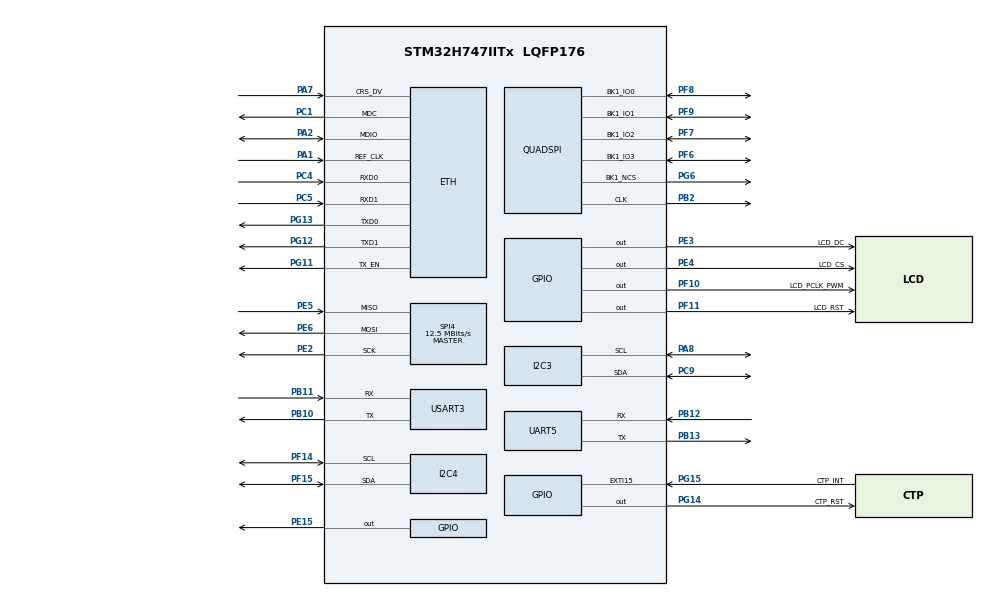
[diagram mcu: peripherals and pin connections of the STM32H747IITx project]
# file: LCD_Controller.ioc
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CORTEX_M7.CPU_DCache=Enabled
CORTEX_M7.CPU_ICache=Enabled
CORTEX_M7.default_mode_Activation=1
CortexM4.IPs=BDMA,CORTEX_M4\:I,DMA,FATFS_M4\:I,FREERTOS_M4\:I,GPIO,IWDG2\:I,MDMA,NVIC2\:I,OPENAMP_M4\:I,PDM2PCM_M4\:I,PWR,RCC,RESMGR_UTILITY,SYS_M4\:I,USB_DEVICE_M4\:I,USB_HOST_M4\:I,VREFBUF,WWDG2\:I
CortexM7.IPs=BDMA\:I,CORTEX_M7\:I,DMA\:I,FATFS_M7\:I,FREERTOS_M7\:I,GPIO\:I,IWDG1\:I,MDMA\:I,NVIC1\:I,OPENAMP_M7\:I,PDM2PCM_M7\:I,PWR\:I,RCC\:I,RESMGR_UTILITY\:I,SYS\:I,USB_DEVICE_M7\:I,USB_HOST_M7\:I,VREFBUF\:I,WWDG1\:I,MEMORYMAP\:I,TIM6\:I,ETH\:I,LWIP\:I,DEBUG\:I,UART5\:I,USART3\:I,SPI4\:I,I2C4\:I,QUADSPI\:I,I2C3\:I
CortexM7.Pins=PE3,PE4,PF10,PF11,PE15,PG14,PG15
ETH.MediaInterface=HAL_ETH_RMII_MODE
ETH.RxDescAddress=0x30040000
ETH.TxDescAddress=0x30040100
FREERTOS_M7.HEAP_NUMBER=3
FREERTOS_M7.Tasks01=defaultTask,24,2048,StartDefaultTask,Default,NULL,Dynamic,NULL,NULL
FREERTOS_M7.configCHECK_FOR_STACK_OVERFLOW=1
FREERTOS_M7.configMAX_TASK_NAME_LEN=50
FREERTOS_M7.configMINIMAL_STACK_SIZE=512
FREERTOS_M7.configTOTAL_HEAP_SIZE=204800
FREERTOS_M7.configUSE_NEWLIB_REENTRANT=1
I2C3.Timing=0x10C0ECFF
I2C4.Speed=50
I2C4.Timing=0x50404CFD
LWIP.BSP.number=1
LWIP.DEFAULT_THREAD_STACKSIZE=2048
LWIP.GATEWAY_ADDRESS=010.002.001.001
LWIP.IP_ADDRESS=010.002.001.110
LWIP.LWIP_DHCP=0
LWIP.LWIP_HTTPD=1
LWIP.LWIP_RAM_HEAP_POINTER=0x30020000
LWIP.MEM_SIZE=131048
LWIP.NETMASK_ADDRESS=255.255.255.000
LWIP.TCPIP_THREAD_STACKSIZE=2048
LWIP.TCP_MSS=1460
LWIP.TCP_SND_BUF=5840
LWIP.TCP_SND_QUEUELEN=16
LWIP.TCP_WND=5840
LWIP.Version=v2.1.2_Cube
LWIP0.BSP.STBoard=false
LWIP0.BSP.api=BSP_COMPONENT_DRIVER
LWIP0.BSP.component=LAN8742
LWIP0.BSP.instance=LAN8742
LWIP0.BSP.name=Driver_PHY
LWIP0.BSP.semaphore=S_LAN8742
LWIP0.BSP.solution=LAN8742
Mcu.Family=STM32H7
Mcu.Name=STM32H747IITx
Mcu.Package=LQFP176
NVIC1.ETH_IRQn=true\:5\:0\:false\:false\:true\:true\:true\:true\:true
NVIC1.EXTI15_10_IRQn=true\:5\:0\:false\:false\:true\:false\:true\:true\:true
NVIC1.PriorityGroup=NVIC_PRIORITYGROUP_4
NVIC1.TIM6_DAC_IRQn=true\:15\:0\:false\:false\:true\:false\:false\:true\:true
NVIC1.TimeBase=TIM6_DAC_IRQn
NVIC1.TimeBaseIP=TIM6
NVIC2.PriorityGroup=NVIC_PRIORITYGROUP_4
PA1.Mode=RMII
PA1.PinAttribute=CortexM7
PA1.Signal=ETH_REF_CLK
PA13\ (JTMS/SWDIO).Mode=Serial_Wire
PA13\ (JTMS/SWDIO).PinAttribute=CortexM7
PA13\ (JTMS/SWDIO).Signal=DEBUG_JTMS-SWDIO
PA14\ (JTCK/SWCLK).Mode=Serial_Wire
PA14\ (JTCK/SWCLK).PinAttribute=CortexM7
PA14\ (JTCK/SWCLK).Signal=DEBUG_JTCK-SWCLK
PA2.Mode=RMII
PA2.PinAttribute=CortexM7
PA2.Signal=ETH_MDIO
PA7.Mode=RMII
PA7.PinAttribute=CortexM7
PA7.Signal=ETH_CRS_DV
PA8.Mode=I2C
PA8.PinAttribute=CortexM7
PA8.Signal=I2C3_SCL
PB10.Mode=Asynchronous
PB10.PinAttribute=CortexM7
PB10.Signal=USART3_TX
PB11.Mode=Asynchronous
PB11.PinAttribute=CortexM7
PB11.Signal=USART3_RX
PB12.Mode=Asynchronous
PB12.PinAttribute=CortexM7
PB12.Signal=UART5_RX
PB13.Mode=Asynchronous
PB13.PinAttribute=CortexM7
PB13.Signal=UART5_TX
PB2.Mode=Single Bank 1
PB2.PinAttribute=CortexM7
PB2.Signal=QUADSPI_CLK
PC1.Mode=RMII
PC1.PinAttribute=CortexM7
PC1.Signal=ETH_MDC
PC4.Mode=RMII
PC4.PinAttribute=CortexM7
PC4.Signal=ETH_RXD0
PC5.Mode=RMII
PC5.PinAttribute=CortexM7
PC5.Signal=ETH_RXD1
PC9.Mode=I2C
PC9.PinAttribute=CortexM7
PC9.Signal=I2C3_SDA
PE15.PinAttribute=CortexM7
PE15.PinState=GPIO_PIN_SET
PE15.Signal=GPIO_Output
PE2.Mode=Full_Duplex_Master
PE2.PinAttribute=CortexM7
PE2.Signal=SPI4_SCK
PE3.GPIO_Label=LCD_DC
PE3.GPIO_Speed=GPIO_SPEED_FREQ_VERY_HIGH
PE3.PinAttribute=CortexM7
PE3.PinState=GPIO_PIN_SET
PE3.Signal=GPIO_Output
PE4.GPIO_Label=LCD_CS
PE4.GPIO_Speed=GPIO_SPEED_FREQ_VERY_HIGH
PE4.PinAttribute=CortexM7
PE4.PinState=GPIO_PIN_SET
PE4.Signal=GPIO_Output
PE5.Mode=Full_Duplex_Master
PE5.PinAttribute=CortexM7
PE5.Signal=SPI4_MISO
PE6.Mode=Full_Duplex_Master
PE6.PinAttribute=CortexM7
PE6.Signal=SPI4_MOSI
PF10.GPIO_Label=LCD_PCLK_PWM
PF10.GPIO_Speed=GPIO_SPEED_FREQ_VERY_HIGH
PF10.PinAttribute=CortexM7
PF10.PinState=GPIO_PIN_SET
PF10.Signal=GPIO_Output
PF11.GPIO_Label=LCD_RST
PF11.GPIO_Speed=GPIO_SPEED_FREQ_VERY_HIGH
PF11.PinAttribute=CortexM7
PF11.PinState=GPIO_PIN_SET
PF11.Signal=GPIO_Output
PF14.GPIO_Pu=GPIO_PULLUP
PF14.GPIO_Speed=GPIO_SPEED_FREQ_VERY_HIGH
PF14.Mode=I2C
PF14.PinAttribute=CortexM7
PF14.Signal=I2C4_SCL
PF15.GPIO_Pu=GPIO_PULLUP
PF15.GPIO_Speed=GPIO_SPEED_FREQ_VERY_HIGH
PF15.Mode=I2C
PF15.PinAttribute=CortexM7
PF15.Signal=I2C4_SDA
PF6.Mode=Single Bank 1
PF6.PinAttribute=CortexM7
PF6.Signal=QUADSPI_BK1_IO3
PF7.Mode=Single Bank 1
PF7.PinAttribute=CortexM7
PF7.Signal=QUADSPI_BK1_IO2
PF8.Mode=Single Bank 1
PF8.PinAttribute=CortexM7
PF8.Signal=QUADSPI_BK1_IO0
PF9.Mode=Single Bank 1
PF9.PinAttribute=CortexM7
PF9.Signal=QUADSPI_BK1_IO1
PG11.Mode=RMII
PG11.PinAttribute=CortexM7
PG11.Signal=ETH_TX_EN
PG12.Mode=RMII
PG12.PinAttribute=CortexM7
PG12.Signal=ETH_TXD1
PG13.Mode=RMII
PG13.PinAttribute=CortexM7
PG13.Signal=ETH_TXD0
PG14.GPIO_Label=CTP_RST
PG14.GPIO_Speed=GPIO_SPEED_FREQ_HIGH
PG14.PinAttribute=CortexM7
PG14.PinState=GPIO_PIN_SET
PG14.Signal=GPIO_Output
PG15.GPIO_Label=CTP_INT
PG15.GPIO_ModeDefaultEXTI=GPIO_MODE_IT_FALLING
PG15.PinAttribute=CortexM7
PG15.Signal=GPXTI15
PG6.Mode=Single Bank 1
PG6.PinAttribute=CortexM7
PG6.Signal=QUADSPI_BK1_NCS
PH0-OSC_IN\ (PH0).Mode=HSE-External-Oscillator
PH0-OSC_IN\ (PH0).PinAttribute=Free
PH0-OSC_IN\ (PH0).Signal=RCC_OSC_IN
PH1-OSC_OUT\ (PH1).Mode=HSE-External-Oscillator
PH1-OSC_OUT\ (PH1).PinAttribute=Free
PH1-OSC_OUT\ (PH1).Signal=RCC_OSC_OUT
ProjectManager.HeapSize=M4-0x200,M7-0x200
ProjectManager.StackSize=M4-0x400,M7-0x400
ProjectManager.TargetToolchain=STM32CubeIDE
QUADSPI.ChipSelectHighTime=QSPI_CS_HIGH_TIME_2_CYCLE
QUADSPI.ClockPrescaler=8
QUADSPI.FifoThreshold=4
QUADSPI.FlashSize=21
QUADSPI.SampleShifting=QSPI_SAMPLE_SHIFTING_HALFCYCLE
RCC.ADCFreq_Value=50390625
RCC.APB1Freq_Value=100000000
RCC.APB2Freq_Value=100000000
RCC.APB3Freq_Value=100000000
RCC.APB4Freq_Value=100000000
RCC.CortexFreq_Value=400000000
RCC.D1PPRE=RCC_APB3_DIV2
RCC.D2PPRE1=RCC_APB1_DIV2
RCC.D2PPRE2=RCC_APB2_DIV2
RCC.D3PPRE=RCC_APB4_DIV2
RCC.DIVM1=2
RCC.DIVN1=64
RCC.HCLKFreq_Value=200000000
RCC.HPRE=RCC_HCLK_DIV2
RCC.PLLFRACN=0
RCC.PLLSourceVirtual=RCC_PLLSOURCE_HSE
RCC.SYSCLKFreq_VALUE=400000000
RCC.SYSCLKSource=RCC_SYSCLKSOURCE_PLLCLK
RCC.USBFreq_Value=400000000
SPI4.BaudRatePrescaler=SPI_BAUDRATEPRESCALER_8
SPI4.CalculateBaudRate=12.5 MBits/s
SPI4.DataSize=SPI_DATASIZE_8BIT
SPI4.Direction=SPI_DIRECTION_2LINES
SPI4.Mode=SPI_MODE_MASTER
SPI4.VirtualType=VM_MASTER
SYS.userName=SYS_M7
USART3.VirtualMode-Asynchronous=VM_ASYNC
VP_FREERTOS_M7_VS_CMSIS_V2.Mode=CMSIS_V2
VP_LWIP_VS_Enabled.Mode=Enabled
VP_MEMORYMAP_VS_MEMORYMAP.Mode=CurAppReg
VP_SYS_M4_VS_Systick.Mode=SysTick
VP_SYS_VS_tim6.Mode=TIM6
board=custom

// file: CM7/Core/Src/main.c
/* USER CODE BEGIN Header */
/**
  ******************************************************************************
  * @file           : main.c
  * @brief          : Main program body
  ******************************************************************************
  * @attention
  *
  * Copyright (c) 2025 STMicroelectronics.
  * All rights reserved.
  *
  * This software is licensed under terms that can be found in the LICENSE file
  * in the root directory of this software component.
  * If no LICENSE file comes with this software, it is provided AS-IS.
  *
  ******************************************************************************
  */
/* USER CODE END Header */

#include "main.h"
#include "cmsis_os.h"
#include "lwip.h"

/* USER CODE BEGIN Includes */
#include "freertos_custom.h"
/* USER CODE END Includes */

/* USER CODE BEGIN PD */
#define DUAL_CORE_BOOT_SYNC_SEQUENCE
#if defined(DUAL_CORE_BOOT_SYNC_SEQUENCE)
#ifndef HSEM_ID_0
#define HSEM_ID_0 (0U)
#endif
#endif
/* USER CODE END PD */

I2C_HandleTypeDef hi2c3;
I2C_HandleTypeDef hi2c4;
QSPI_HandleTypeDef hqspi;
SPI_HandleTypeDef hspi4;
UART_HandleTypeDef huart5;
UART_HandleTypeDef huart3;

/* Definitions for defaultTask */
osThreadId_t defaultTaskHandle;
const osThreadAttr_t defaultTask_attributes = {
  .name = "defaultTask",
  .stack_size = 10000 * 4,
  .priority = (osPriority_t) osPriorityNormal,
};

void SystemClock_Config(void);
static void MPU_Config(void);
static void MX_GPIO_Init(void);
static void MX_SPI4_Init(void);
static void MX_UART5_Init(void);
static void MX_USART3_UART_Init(void);
static void MX_I2C4_Init(void);
static void MX_QUADSPI_Init(void);
static void MX_I2C3_Init(void);
void StartDefaultTask(void *argument);
/* USER CODE BEGIN PFP */
static void simple_httpd_init(void *arg);
/* USER CODE END PFP */

/* USER CODE BEGIN 0 */
int __io_putchar(int ch)
{
    HAL_UART_Transmit(&huart5, (uint8_t *)&ch, 1, 100);
    return ch;
}
/* USER CODE END 0 */

int main(void)
{

  /* MPU Configuration--------------------------------------------------------*/
  MPU_Config();

  /* Enable CPU Cache */
  SCB_EnableICache();
  SCB_EnableDCache();

  /* MCU Configuration--------------------------------------------------------*/
  HAL_Init();
  SystemClock_Config();

  /* Initialize all configured peripherals */
  MX_GPIO_Init();
  MX_SPI4_Init();
  MX_UART5_Init();
  MX_USART3_UART_Init();
  MX_I2C4_Init();
  MX_QUADSPI_Init();
  MX_I2C3_Init();

  /* Initialize Ethernet backend (LwIP CGI/SSI setup) */
  Ethernet_BackendInfrastructure_Init();

  /* Init FreeRTOS kernel */
  osKernelInitialize();

  /* Create application threads */
  MainProcessFreertosInit();

  /* Default LWIP task */
  defaultTaskHandle = osThreadNew(StartDefaultTask, NULL, &defaultTask_attributes);

  /* Start scheduler */
  osKernelStart();

  /* Infinite loop */
  while (1)
  {
  }
}

void SystemClock_Config(void)
{
  RCC_OscInitTypeDef RCC_OscInitStruct = {0};
  RCC_ClkInitTypeDef RCC_ClkInitStruct = {0};

  HAL_PWREx_ConfigSupply(PWR_DIRECT_SMPS_SUPPLY);
  __HAL_PWR_VOLTAGESCALING_CONFIG(PWR_REGULATOR_VOLTAGE_SCALE1);
  while(!__HAL_PWR_GET_FLAG(PWR_FLAG_VOSRDY)) {}

  RCC_OscInitStruct.OscillatorType = RCC_OSCILLATORTYPE_HSE;
  RCC_OscInitStruct.HSEState = RCC_HSE_ON;
  RCC_OscInitStruct.PLL.PLLState = RCC_PLL_ON;
  RCC_OscInitStruct.PLL.PLLSource = RCC_PLLSOURCE_HSE;
  RCC_OscInitStruct.PLL.PLLM = 2;
  RCC_OscInitStruct.PLL.PLLN = 64;
  RCC_OscInitStruct.PLL.PLLP = 2;
  RCC_OscInitStruct.PLL.PLLQ = 2;
  RCC_OscInitStruct.PLL.PLLR = 2;
  RCC_OscInitStruct.PLL.PLLRGE = RCC_PLL1VCIRANGE_3;
  RCC_OscInitStruct.PLL.PLLVCOSEL = RCC_PLL1VCOWIDE;
  RCC_OscInitStruct.PLL.PLLFRACN = 0;
  if (HAL_RCC_OscConfig(&RCC_OscInitStruct) != HAL_OK) { Error_Handler(); }

  RCC_ClkInitStruct.ClockType = RCC_CLOCKTYPE_HCLK | RCC_CLOCKTYPE_SYSCLK
                              | RCC_CLOCKTYPE_PCLK1 | RCC_CLOCKTYPE_PCLK2
                              | RCC_CLOCKTYPE_D3PCLK1 | RCC_CLOCKTYPE_D1PCLK1;
  RCC_ClkInitStruct.SYSCLKSource = RCC_SYSCLKSOURCE_PLLCLK;
  RCC_ClkInitStruct.SYSCLKDivider = RCC_SYSCLK_DIV1;
  RCC_ClkInitStruct.AHBCLKDivider = RCC_HCLK_DIV2;
  RCC_ClkInitStruct.APB3CLKDivider = RCC_APB3_DIV2;
  RCC_ClkInitStruct.APB1CLKDivider = RCC_APB1_DIV2;
  RCC_ClkInitStruct.APB2CLKDivider = RCC_APB2_DIV2;
  RCC_ClkInitStruct.APB4CLKDivider = RCC_APB4_DIV2;

  if (HAL_RCC_ClockConfig(&RCC_ClkInitStruct, FLASH_LATENCY_2) != HAL_OK)
  {
    Error_Handler();
  }
}

/* --------------------------- Peripherals Init ---------------------------- */

static void MX_I2C3_Init(void)
{
  hi2c3.Instance = I2C3;
  hi2c3.Init.Timing = 0x10C0ECFF;
  hi2c3.Init.OwnAddress1 = 0;
  hi2c3.Init.AddressingMode = I2C_ADDRESSINGMODE_7BIT;
  hi2c3.Init.DualAddressMode = I2C_DUALADDRESS_DISABLE;
  hi2c3.Init.OwnAddress2 = 0;
  hi2c3.Init.OwnAddress2Masks = I2C_OA2_NOMASK;
  hi2c3.Init.GeneralCallMode = I2C_GENERALCALL_DISABLE;
  hi2c3.Init.NoStretchMode = I2C_NOSTRETCH_DISABLE;
  if (HAL_I2C_Init(&hi2c3) != HAL_OK) { Error_Handler(); }
  if (HAL_I2CEx_ConfigAnalogFilter(&hi2c3, I2C_ANALOGFILTER_ENABLE) != HAL_OK) { Error_Handler(); }
  if (HAL_I2CEx_ConfigDigitalFilter(&hi2c3, 0) != HAL_OK) { Error_Handler(); }
}

static void MX_I2C4_Init(void)
{
  hi2c4.Instance = I2C4;
  hi2c4.Init.Timing = 0x50404CFD;
  hi2c4.Init.OwnAddress1 = 0;
  hi2c4.Init.AddressingMode = I2C_ADDRESSINGMODE_7BIT;
  hi2c4.Init.DualAddressMode = I2C_DUALADDRESS_DISABLE;
  hi2c4.Init.OwnAddress2 = 0;
  hi2c4.Init.OwnAddress2Masks = I2C_OA2_NOMASK;
  hi2c4.Init.GeneralCallMode = I2C_GENERALCALL_DISABLE;
  hi2c4.Init.NoStretchMode = I2C_NOSTRETCH_DISABLE;
  if (HAL_I2C_Init(&hi2c4) != HAL_OK) { Error_Handler(); }
  if (HAL_I2CEx_ConfigAnalogFilter(&hi2c4, I2C_ANALOGFILTER_ENABLE) != HAL_OK) { Error_Handler(); }
  if (HAL_I2CEx_ConfigDigitalFilter(&hi2c4, 0) != HAL_OK) { Error_Handler(); }
}

static void MX_QUADSPI_Init(void)
{
  hqspi.Instance = QUADSPI;
  hqspi.Init.ClockPrescaler = 8;
  hqspi.Init.FifoThreshold = 4;
  hqspi.Init.SampleShifting = QSPI_SAMPLE_SHIFTING_HALFCYCLE;
  hqspi.Init.FlashSize = 21;
  hqspi.Init.ChipSelectHighTime = QSPI_CS_HIGH_TIME_2_CYCLE;
  hqspi.Init.ClockMode = QSPI_CLOCK_MODE_0;
  hqspi.Init.FlashID = QSPI_FLASH_ID_1;
  hqspi.Init.DualFlash = QSPI_DUALFLASH_DISABLE;
  if (HAL_QSPI_Init(&hqspi) != HAL_OK) { Error_Handler(); }
}

static void MX_SPI4_Init(void)
{
  hspi4.Instance = SPI4;
  hspi4.Init.Mode = SPI_MODE_MASTER;
  hspi4.Init.Direction = SPI_DIRECTION_2LINES;
  hspi4.Init.DataSize = SPI_DATASIZE_8BIT;
  hspi4.Init.CLKPolarity = SPI_POLARITY_LOW;
  hspi4.Init.CLKPhase = SPI_PHASE_1EDGE;
  hspi4.Init.NSS = SPI_NSS_SOFT;
  hspi4.Init.BaudRatePrescaler = SPI_BAUDRATEPRESCALER_8;
  hspi4.Init.FirstBit = SPI_FIRSTBIT_MSB;
  hspi4.Init.TIMode = SPI_TIMODE_DISABLE;
  hspi4.Init.CRCCalculation = SPI_CRCCALCULATION_DISABLE;
  hspi4.Init.CRCPolynomial = 0x0;
  hspi4.Init.NSSPMode = SPI_NSS_PULSE_ENABLE;
  hspi4.Init.NSSPolarity = SPI_NSS_POLARITY_LOW;
  hspi4.Init.FifoThreshold = SPI_FIFO_THRESHOLD_01DATA;
  if (HAL_SPI_Init(&hspi4) != HAL_OK) { Error_Handler(); }
}

static void MX_UART5_Init(void)
{
  huart5.Instance = UART5;
  huart5.Init.BaudRate = 115200;
  huart5.Init.WordLength = UART_WORDLENGTH_8B;
  huart5.Init.StopBits = UART_STOPBITS_1;
  huart5.Init.Parity = UART_PARITY_NONE;
  huart5.Init.Mode = UART_MODE_TX_RX;
  huart5.Init.HwFlowCtl = UART_HWCONTROL_NONE;
  huart5.Init.OverSampling = UART_OVERSAMPLING_16;
  huart5.Init.OneBitSampling = UART_ONE_BIT_SAMPLE_DISABLE;
  huart5.Init.ClockPrescaler = UART_PRESCALER_DIV1;
  huart5.AdvancedInit.AdvFeatureInit = UART_ADVFEATURE_NO_INIT;
  if (HAL_UART_Init(&huart5) != HAL_OK) { Error_Handler(); }
}

static void MX_USART3_UART_Init(void)
{
  huart3.Instance = USART3;
  huart3.Init.BaudRate = 115200;
  huart3.Init.WordLength = UART_WORDLENGTH_8B;
  huart3.Init.StopBits = UART_STOPBITS_1;
  huart3.Init.Parity = UART_PARITY_NONE;
  huart3.Init.Mode = UART_MODE_TX_RX;
  huart3.Init.HwFlowCtl = UART_HWCONTROL_NONE;
  huart3.Init.OverSampling = UART_OVERSAMPLING_16;
  huart3.Init.OneBitSampling = UART_ONE_BIT_SAMPLE_DISABLE;
  huart3.Init.ClockPrescaler = UART_PRESCALER_DIV1;
  huart3.AdvancedInit.AdvFeatureInit = UART_ADVFEATURE_NO_INIT;
  if (HAL_UART_Init(&huart3) != HAL_OK) { Error_Handler(); }
}

/* --------------------------- GPIO Init ---------------------------- */

static void MX_GPIO_Init(void)
{
  GPIO_InitTypeDef GPIO_InitStruct = {0};

  __HAL_RCC_GPIOE_CLK_ENABLE();
  __HAL_RCC_GPIOF_CLK_ENABLE();
  __HAL_RCC_GPIOC_CLK_ENABLE();
  __HAL_RCC_GPIOA_CLK_ENABLE();
  __HAL_RCC_GPIOB_CLK_ENABLE();
  __HAL_RCC_GPIOG_CLK_ENABLE();

  HAL_GPIO_WritePin(GPIOE, LCD_DC_Pin | LCD_CS_Pin | GPIO_PIN_15, GPIO_PIN_SET);
  HAL_GPIO_WritePin(GPIOF, LCD_PCLK_PWM_Pin | LCD_RST_Pin, GPIO_PIN_SET);
  HAL_GPIO_WritePin(CTP_RST_GPIO_Port, CTP_RST_Pin, GPIO_PIN_SET);

  GPIO_InitStruct.Pin = LCD_DC_Pin | LCD_CS_Pin;
  GPIO_InitStruct.Mode = GPIO_MODE_OUTPUT_PP;
  GPIO_InitStruct.Pull = GPIO_NOPULL;
  GPIO_InitStruct.Speed = GPIO_SPEED_FREQ_VERY_HIGH;
  HAL_GPIO_Init(GPIOE, &GPIO_InitStruct);

  GPIO_InitStruct.Pin = LCD_PCLK_PWM_Pin | LCD_RST_Pin;
  GPIO_InitStruct.Mode = GPIO_MODE_OUTPUT_PP;
  GPIO_InitStruct.Pull = GPIO_NOPULL;
  GPIO_InitStruct.Speed = GPIO_SPEED_FREQ_VERY_HIGH;
  HAL_GPIO_Init(GPIOF, &GPIO_InitStruct);

  GPIO_InitStruct.Pin = CTP_RST_Pin;
  GPIO_InitStruct.Mode = GPIO_MODE_OUTPUT_PP;
  GPIO_InitStruct.Pull = GPIO_NOPULL;
  GPIO_InitStruct.Speed = GPIO_SPEED_FREQ_HIGH;
  HAL_GPIO_Init(CTP_RST_GPIO_Port, &GPIO_InitStruct);

  GPIO_InitStruct.Pin = CTP_INT_Pin;
  GPIO_InitStruct.Mode = GPIO_MODE_IT_FALLING;
  GPIO_InitStruct.Pull = GPIO_NOPULL;
  HAL_GPIO_Init(CTP_INT_GPIO_Port, &GPIO_InitStruct);

  HAL_NVIC_SetPriority(CTP_INT_EXTI_IRQn, 5, 0);
  HAL_NVIC_EnableIRQ(CTP_INT_EXTI_IRQn);
}

/* --------------------------- LWIP & HTTP ---------------------------- */
static void simple_httpd_init(void *arg)
{
    httpd_init();
    EthernetBackend_RegisterCGIHandlers();
    EthernetBackend_RegisterSSIHandler();
}

void StartDefaultTask(void *argument)
{
  MX_LWIP_Init();
  osDelay(3000);
  tcpip_callback(simple_httpd_init, NULL);
  printf("[DEFAULT] LWIP and HTTP initialized\r\n");

  for(;;) { osDelay(1000); }
}

/* --------------------------- MPU Config ---------------------------- */
void MPU_Config(void)
{
  MPU_Region_InitTypeDef MPU_InitStruct = {0};
  HAL_MPU_Disable();

  MPU_InitStruct.Enable = MPU_REGION_ENABLE;
  MPU_InitStruct.Number = MPU_REGION_NUMBER0;
  MPU_InitStruct.BaseAddress = 0x0;
  MPU_InitStruct.Size = MPU_REGION_SIZE_4GB;
  MPU_InitStruct.SubRegionDisable = 0x87;
  MPU_InitStruct.TypeExtField = MPU_TEX_LEVEL0;
  MPU_InitStruct.AccessPermission = MPU_REGION_NO_ACCESS;
  MPU_InitStruct.DisableExec = MPU_INSTRUCTION_ACCESS_DISABLE;
  MPU_InitStruct.IsShareable = MPU_ACCESS_SHAREABLE;
  MPU_InitStruct.IsCacheable = MPU_ACCESS_NOT_CACHEABLE;
  MPU_InitStruct.IsBufferable = MPU_ACCESS_NOT_BUFFERABLE;
  HAL_MPU_ConfigRegion(&MPU_InitStruct);

  /* D2 SRAM for Ethernet */
  MPU_InitStruct.Number = MPU_REGION_NUMBER1;
  MPU_InitStruct.BaseAddress = 0x30020000;
  MPU_InitStruct.Size = MPU_REGION_SIZE_128KB;
  MPU_InitStruct.AccessPermission = MPU_REGION_FULL_ACCESS;
  MPU_InitStruct.IsCacheable = 0;
  MPU_InitStruct.IsBufferable = 0;
  MPU_InitStruct.IsShareable = 1;
  HAL_MPU_ConfigRegion(&MPU_InitStruct);

  /* QSPI Memory */
  MPU_InitStruct.Number = MPU_REGION_NUMBER3;
  MPU_InitStruct.BaseAddress = 0x90000000;
  MPU_InitStruct.Size = MPU_REGION_SIZE_4MB;
  MPU_InitStruct.AccessPermission = MPU_REGION_FULL_ACCESS;
  MPU_InitStruct.IsCacheable = 1;
  MPU_InitStruct.IsBufferable = 0;
  MPU_InitStruct.IsShareable = 0;
  HAL_MPU_ConfigRegion(&MPU_InitStruct);

  /* Flash Region */
  MPU_InitStruct.Number = MPU_REGION_NUMBER4;
  MPU_InitStruct.BaseAddress = 0x08000000;
  MPU_InitStruct.Size = MPU_REGION_SIZE_2MB;
  MPU_InitStruct.AccessPermission = MPU_REGION_FULL_ACCESS;
  MPU_InitStruct.IsCacheable = 1;
  MPU_InitStruct.IsBufferable = 0;
  MPU_InitStruct.IsShareable = 0;
  HAL_MPU_ConfigRegion(&MPU_InitStruct);

  HAL_MPU_Enable(MPU_PRIVILEGED_DEFAULT);
}

/* --------------------------- Error Handler ---------------------------- */
void Error_Handler(void)
{
  __disable_irq();
  while (1) {}
}
